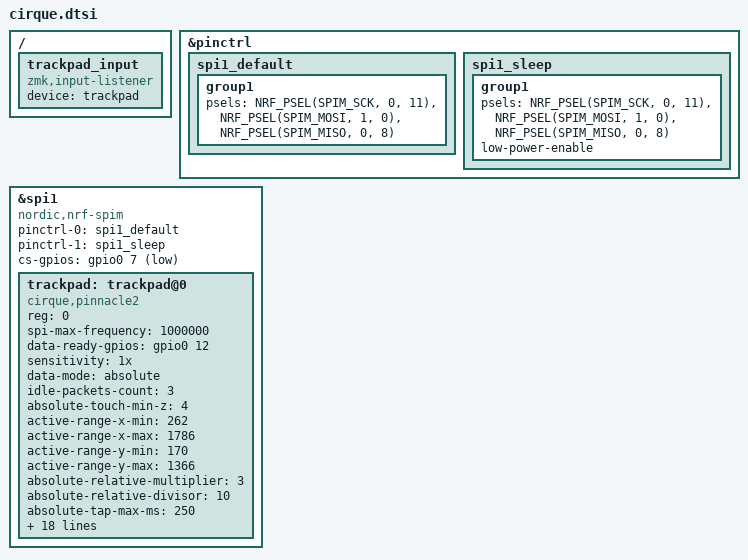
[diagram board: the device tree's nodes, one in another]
/*
 * Cirque Pinnacle 1CA027 trackpad (SPI) on the right (central) half.
 *
 * Pins: SCK = P0.11, MOSI = P1.00, MISO = P0.08, CS = P0.07,
 *       DR (data ready) = P0.12 (active high).
 */

&pinctrl {
    spi1_default: spi1_default {
        group1 {
            psels = <NRF_PSEL(SPIM_SCK, 0, 11)>,
                    <NRF_PSEL(SPIM_MOSI, 1, 0)>,
                    <NRF_PSEL(SPIM_MISO, 0, 8)>;
        };
    };

    spi1_sleep: spi1_sleep {
        group1 {
            psels = <NRF_PSEL(SPIM_SCK, 0, 11)>,
                    <NRF_PSEL(SPIM_MOSI, 1, 0)>,
                    <NRF_PSEL(SPIM_MISO, 0, 8)>;
            low-power-enable;
        };
    };
};

&spi1 {
    status = "okay";
    compatible = "nordic,nrf-spim";
    pinctrl-0 = <&spi1_default>;
    pinctrl-1 = <&spi1_sleep>;
    pinctrl-names = "default", "sleep";
    cs-gpios = <&gpio0 7 GPIO_ACTIVE_LOW>;

    trackpad: trackpad@0 {
        compatible = "cirque,pinnacle2";
        reg = <0>;
        spi-max-frequency = <1000000>;
        data-ready-gpios = <&gpio0 12 GPIO_ACTIVE_HIGH>;
        sensitivity = "1x";
        data-mode = "absolute";
        idle-packets-count = <3>;
        absolute-touch-min-z = <4>;
        /*
         * Measured usable area. The TM035035 is a 35 mm module with a 31 mm
         * sensing area and this housing loses a little more, so the outer
         * ~15% of the grid is dead: taps on the visible rim produce no touch
         * event at all, and the outermost reachable samples sit around
         * 70-78% of the default range. Shrink the active range by 15% around
         * the centre so 100% means "the edge you can actually touch".
         */
        active-range-x-min = <262>;
        active-range-x-max = <1786>;
        active-range-y-min = <170>;
        active-range-y-max = <1366>;
        absolute-relative-multiplier = <3>;
        absolute-relative-divisor = <10>;
        /*
         * TM035035 datasheet (v1.2) geometry:
         *   - Pinnacle absolute grid 0..2048 x 0..1536
         *   - clipped active range 128..1920 x 64..1472
         *   - the 31 mm circular sensing area is the ellipse inscribed in that
         *     range (Figure 6), so the reachable rim at 4-6 o'clock has a
         *     smaller x than the rectangle corner.
         *
         * Tap tuning (values are coordinate units; X ~57.8 units/mm,
         * Y ~45.4 units/mm on this 31 mm sensor):
         *  - touch-min-z 8 (was 12): the outermost electrodes couple weaker,
         *    so rim touches were being treated as "no touch" and the scroll
         *    latch kept resetting.
         *  - tap-max-movement 180 (1.5x the original 120): a thumb tap at the
         *    rim rolls a couple of millimetres, so 150 still dropped taps.
         *  - tap-click-ms 50 so a host cannot coalesce the press/release pair.
         */
        absolute-tap-max-ms = <250>;
        absolute-tap-max-movement = <180>;
        absolute-tap-click-ms = <50>;
        absolute-tap-drag-enable;
        absolute-tap-drag-timeout-ms = <300>;
        /* Must be >= tap-max-movement, otherwise the second tap of a
         * double-click is not accepted as a nearby tap for tap-drag. */
        absolute-tap-drag-max-movement = <200>;
        /*
         * Secondary (right) click on a round pad: angular wedge instead of a
         * rectangle. Calibrated against the measured frame on this unit:
         * the thumb cluster sits ~20 degrees off the sensor axes, so the
         * physical 5 o'clock lands at ~46 deg and the physical 6 o'clock at
         * ~65-69 deg. 30..55 degrees therefore covers "5 o'clock" while the
         * bottom centre and the right side stay on the primary button. The
         * centre 30% of the radius is excluded.
         */
        absolute-secondary-tap-wedge-enable;
        absolute-secondary-tap-min-slope-milli = <577>;   /* tan(30 deg) */
        absolute-secondary-tap-max-slope-milli = <1428>;  /* tan(55 deg) */
        /* Rectangle path, unused while the wedge is enabled. */
        /* absolute-secondary-tap-area-width = <620>; */
        /* absolute-secondary-tap-area-height = <430>; */
        absolute-aux-tap-area-width = <0>;
        absolute-aux-tap-area-height = <0>;
        /* Edge motion is off for now: it moves the pointer while the finger
         * rests at the rim, which masks and confuses edge-scroll testing. */
        /* absolute-edge-motion-enable; */
        /* absolute-edge-motion-zone = <80>; */
        /* absolute-edge-motion-speed = <4>; */
        /* absolute-edge-motion-interval-ms = <10>; */
        /* absolute-edge-motion-start-ms = <120>; */
        /*
         * Right-edge scroll, elliptical ring latch. 60 = the outer 40% of the
         * radius (~6.2 mm on the 31 mm sensor). The latch is deferred until
         * the stroke is vertical-dominant (dy >= 2/3 dx), so a wider ring no
         * longer turns sideways strokes into wheel ticks.
         * Divisor 50 = 1 wheel tick per 50 coordinate units (~0.9 mm).
         */
        absolute-right-edge-scroll-enable;
        absolute-edge-scroll-ring-percent = <70>;
        absolute-scroll-zone = <300>;
        absolute-scroll-divisor = <50>;
        /* Datasheet recommendation: clip noisy coordinates to the active
         * range so rim samples cannot fall outside 128..1920 / 64..1472. */
        clipping-enable;
        /* Bring-up instrumentation: log x/y/z and normalized nx/ny on every
         * touch down (visible in DYA Studio -> Devtool). */
        absolute-touch-log-enable;
        startup-delay-ms = <1500>;
        primary-tap-enable;
        /* invert-y and glide-extend-enable are relative-mode only; they are
         * no-ops here because this node runs data-mode = "absolute". */
    };
};

/ {
    trackpad_input: trackpad_input {
        compatible = "zmk,input-listener";
        device = <&trackpad>;
    };
};
